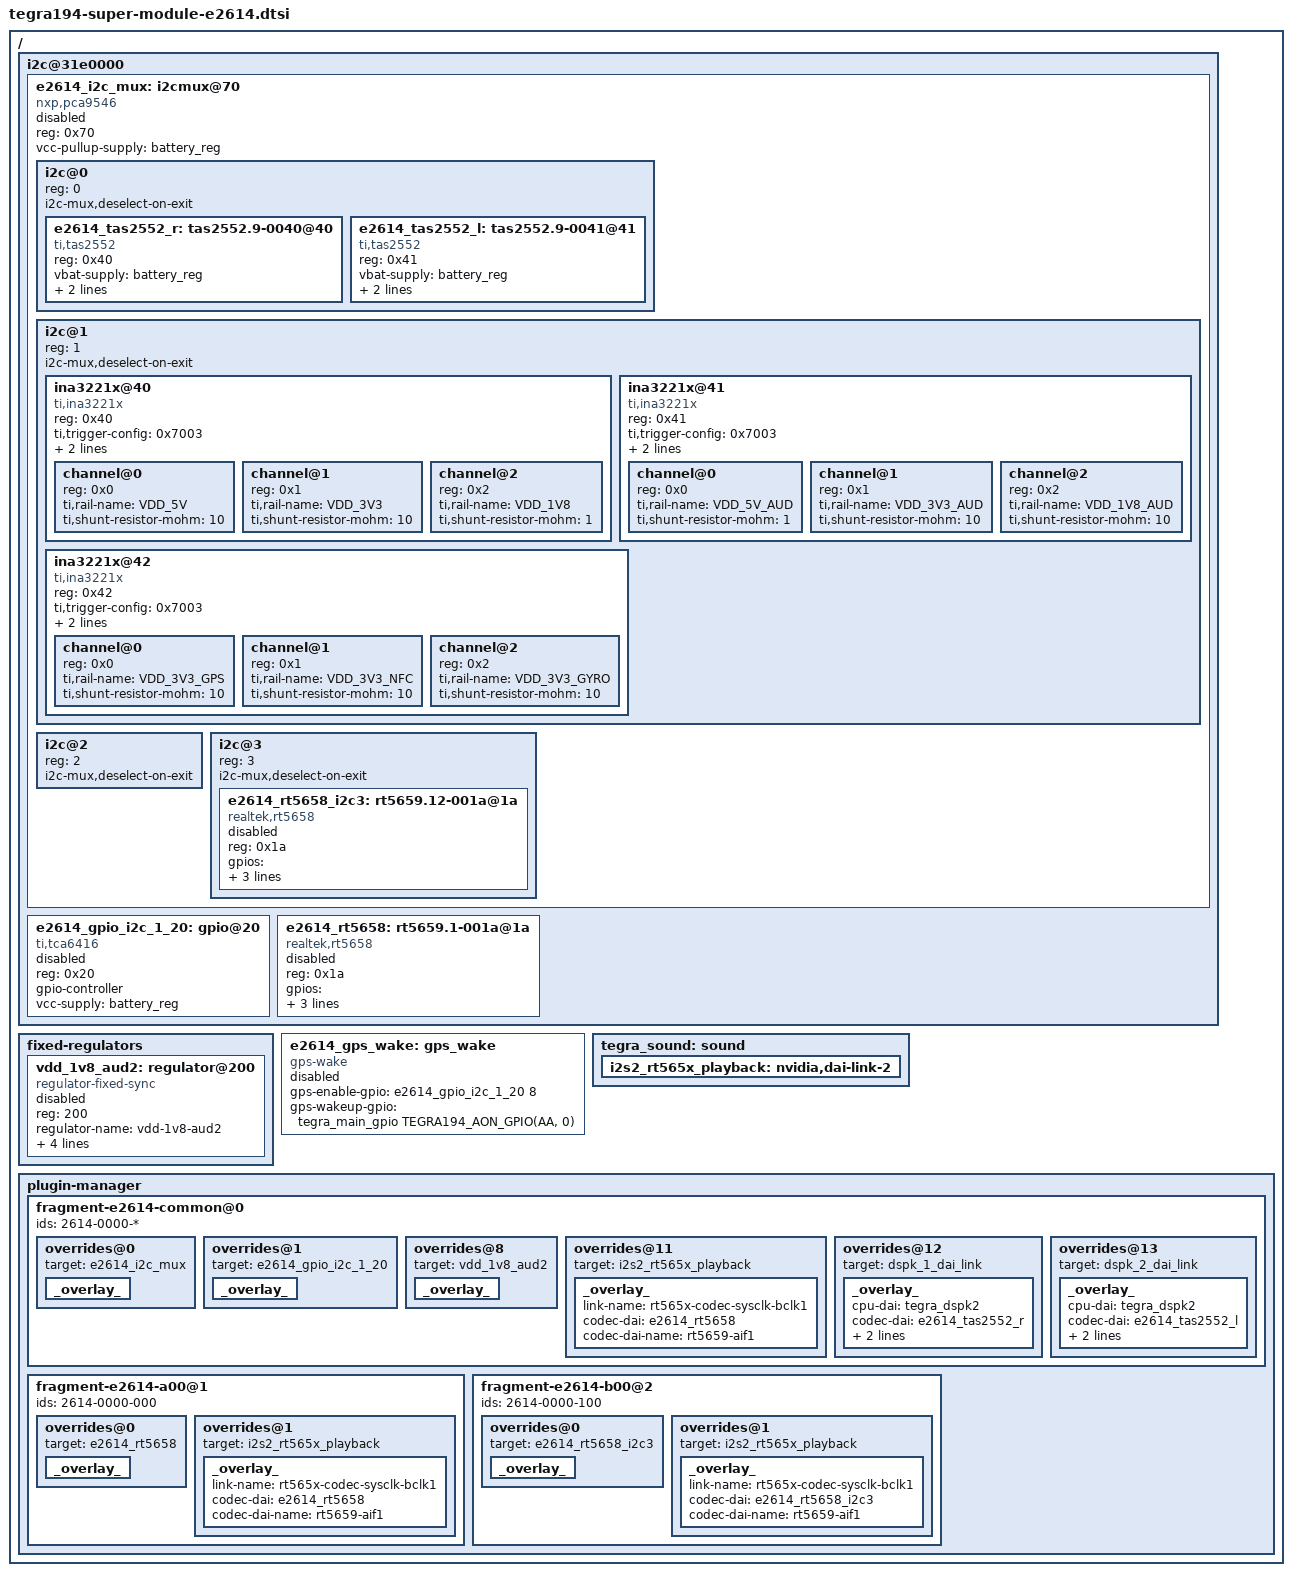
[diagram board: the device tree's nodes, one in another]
/*
 * tegra194-super-module-e2614.dtsi: E2600 DTSI file.
 *
 * Copyright (c) 2018, NVIDIA CORPORATION.  All rights reserved.
 *
 * This program is free software; you can redistribute it and/or modify
 * it under the terms of the GNU General Public License as published by
 * the Free Software Foundation; version 2 of the License.
 *
 * This program is distributed in the hope that it will be useful, but WITHOUT
 * ANY WARRANTY; without even the implied warranty of MERCHANTABILITY or
 * FITNESS FOR A PARTICULAR PURPOSE.  See the GNU General Public License for
 * more details.
 */

/ {
	i2c@31e0000 {
		e2614_i2c_mux: i2cmux@70 {
			compatible = "nxp,pca9546";
			reg = <0x70>;
			#address-cells = <1>;
			#size-cells = <0>;
			vcc-pullup-supply = <&battery_reg>;
			status = "disabled";
			i2c@0 {
				reg = <0>;
				i2c-mux,deselect-on-exit;
				#address-cells = <1>;
				#size-cells = <0>;
				e2614_tas2552_r:tas2552.9-0040@40 {
					compatible = "ti,tas2552";
					reg = <0x40>;
					vbat-supply = <&battery_reg>;
					avdd-supply = <&vdd_1v8_aud2>;
					tas2552,pdm_edge_select = <0>;
				};
				e2614_tas2552_l:tas2552.9-0041@41 {
                                        compatible = "ti,tas2552";
                                        reg = <0x41>;
                                        vbat-supply = <&battery_reg>;
                                        avdd-supply = <&vdd_1v8_aud2>;
					tas2552,pdm_edge_select = <1>;
                                };
			};
			i2c@1 {
				reg = <1>;
				i2c-mux,deselect-on-exit;
				#address-cells = <1>;
				#size-cells = <0>;
				ina3221x@40 {
					compatible = "ti,ina3221x";
					reg = <0x40>;
					ti,trigger-config = <0x7003>;
					ti,continuous-config = <0x7c07>;
					ti,enable-forced-continuous;
					#address-cells = <1>;
					#size-cells = <0>;
					channel@0 {
						reg = <0x0>;
						ti,rail-name = "VDD_5V";
						ti,shunt-resistor-mohm = <10>;
					};
					channel@1 {
						reg = <0x1>;
						ti,rail-name = "VDD_3V3";
						ti,shunt-resistor-mohm = <10>;
					};
					channel@2 {
						reg = <0x2>;
						ti,rail-name = "VDD_1V8";
						ti,shunt-resistor-mohm = <1>;
					};
				};
				ina3221x@41 {
					compatible = "ti,ina3221x";
					reg = <0x41>;
					ti,trigger-config = <0x7003>;
					ti,continuous-config = <0x7c07>;
					ti,enable-forced-continuous;
					#address-cells = <1>;
					#size-cells = <0>;
					channel@0 {
						reg = <0x0>;
						ti,rail-name = "VDD_5V_AUD";
						ti,shunt-resistor-mohm = <1>;
					};
					channel@1 {
						reg = <0x1>;
						ti,rail-name = "VDD_3V3_AUD";
						ti,shunt-resistor-mohm = <10>;
					};
					channel@2 {
						reg = <0x2>;
						ti,rail-name = "VDD_1V8_AUD";
						ti,shunt-resistor-mohm = <10>;
					};
				};
				ina3221x@42 {
					compatible = "ti,ina3221x";
					reg = <0x42>;
					ti,trigger-config = <0x7003>;
					ti,continuous-config = <0x7c07>;
					ti,enable-forced-continuous;
					#address-cells = <1>;
					#size-cells = <0>;
					channel@0 {
						reg = <0x0>;
						ti,rail-name = "VDD_3V3_GPS";
						ti,shunt-resistor-mohm = <10>;
					};
					channel@1 {
						reg = <0x1>;
						ti,rail-name = "VDD_3V3_NFC";
						ti,shunt-resistor-mohm = <10>;
					};
					channel@2 {
						reg = <0x2>;
						ti,rail-name = "VDD_3V3_GYRO";
						ti,shunt-resistor-mohm = <10>;
					};
				};
			};
			i2c@2 {
				reg = <2>;
				i2c-mux,deselect-on-exit;
				#address-cells = <1>;
				#size-cells = <0>;
			};
			i2c@3 {
				reg = <3>;
				i2c-mux,deselect-on-exit;
				#address-cells = <1>;
				#size-cells = <0>;
				e2614_rt5658_i2c3: rt5659.12-001a@1a {
					compatible = "realtek,rt5658";
					reg = <0x1a>;
					status = "disabled";

					/* gpio for jack detection */
					gpios = <&tegra_main_gpio TEGRA194_MAIN_GPIO(R, 0) 0>;

					/* refer include/sound/rt5659.h for the values to be used */
					realtek,jd-src = <1>; /* RT5659_JD3 */
					realtek,dmic1-data-pin = <2>; /* RT5659_DMIC1_DATA_GPIO5 */
				};
			};
		};

		e2614_gpio_i2c_1_20: gpio@20 {
			compatible = "ti,tca6416";
			reg = <0x20>;
			gpio-controller;
			#gpio-cells = <2>;
			vcc-supply = <&battery_reg>;
			status = "disabled";
		};

		e2614_rt5658: rt5659.1-001a@1a {
			compatible = "realtek,rt5658";
			reg = <0x1a>;
			status = "disabled";

			/* gpio for jack detection */
			gpios = <&tegra_main_gpio TEGRA194_MAIN_GPIO(R, 0) 0>;

			/* refer include/sound/rt5659.h for the values to be used */
			realtek,jd-src = <1>; /* RT5659_JD3 */
			realtek,dmic1-data-pin = <2>; /* RT5659_DMIC1_DATA_GPIO5 */
		};
	};

	fixed-regulators {
		vdd_1v8_aud2: regulator@200 {
			compatible = "regulator-fixed-sync";
			reg = <200>;
			regulator-name = "vdd-1v8-aud2";
			regulator-min-microvolt = <1800000>;
			regulator-max-microvolt = <1800000>;
			gpio = <&e2614_gpio_i2c_1_20 11 1>; /*DSPK EN*/
			enable-active-high;
			status = "disabled";
		};
	};

	e2614_gps_wake: gps_wake {
		compatible = "gps-wake";
		gps-enable-gpio = <&e2614_gpio_i2c_1_20 8 0>;
		gps-wakeup-gpio = <&tegra_main_gpio TEGRA194_AON_GPIO(AA, 0) 0>;
		status = "disabled";
	};

	tegra_sound: sound {
		i2s2_rt565x_playback: nvidia,dai-link-2 {
		};
	};

	plugin-manager {
		fragment-e2614-common@0 {
			ids = "2614-0000-*";
			overrides@0 {
				target = <&e2614_i2c_mux>;
				_overlay_ {
					status = "okay";
				};
			};
			overrides@1 {
				target = <&e2614_gpio_i2c_1_20>;
				_overlay_ {
					status = "okay";
				};
			};
			overrides@8 {
				target = <&vdd_1v8_aud2>;
				_overlay_ {
					status = "okay";
				};
			};

			overrides@11 {
				target = <&i2s2_rt565x_playback>;
				_overlay_ {
					link-name = "rt565x-codec-sysclk-bclk1";
					codec-dai = <&e2614_rt5658>;
					codec-dai-name = "rt5659-aif1";
				};
			};
			overrides@12 {
				target = <&dspk_1_dai_link>;
				_overlay_ {
					cpu-dai = <&tegra_dspk2>;
					codec-dai = <&e2614_tas2552_r>;
					cpu-dai-name = "DSPK2";
					codec-dai-name = "tas2552-amplifier";
				};
			};
			overrides@13 {
				target = <&dspk_2_dai_link>;
				_overlay_ {
					cpu-dai = <&tegra_dspk2>;
					codec-dai = <&e2614_tas2552_l>;
					cpu-dai-name = "DSPK2";
					codec-dai-name = "tas2552-amplifier";
				};
			};
		};

		fragment-e2614-a00@1 {
			ids = "2614-0000-000";
			overrides@0 {
				target = <&e2614_rt5658>;
				_overlay_ {
					status = "okay";
				};
			};
			overrides@1 {
				target = <&i2s2_rt565x_playback>;
				_overlay_ {
					link-name = "rt565x-codec-sysclk-bclk1";
					codec-dai = <&e2614_rt5658>;
					codec-dai-name = "rt5659-aif1";
				};
			};
		};

		fragment-e2614-b00@2 {
			ids = "2614-0000-100";
			overrides@0 {
				target = <&e2614_rt5658_i2c3>;
				_overlay_ {
					status = "okay";
				};
			};

			overrides@1 {
				target = <&i2s2_rt565x_playback>;
				_overlay_ {
					link-name = "rt565x-codec-sysclk-bclk1";
					codec-dai = <&e2614_rt5658_i2c3>;
					codec-dai-name = "rt5659-aif1";
				};
			};
		};
	};
};
